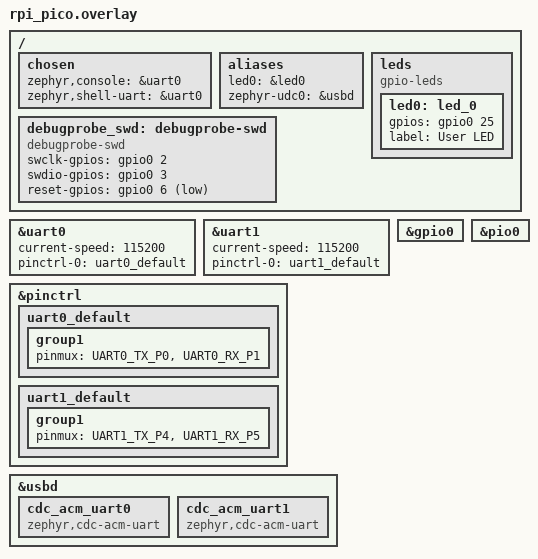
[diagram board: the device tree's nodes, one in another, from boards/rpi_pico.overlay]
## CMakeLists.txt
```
# SPDX-License-Identifier: MIT
# Copyright (c) 2026 Vincent Jardin <vjardin@free.fr>
#
# Debugprobe Zephyr Port - CMakeLists.txt
#
# This is a port of the Raspberry Pi Debug Probe firmware from FreeRTOS to Zephyr.
# Original: https://github.com/raspberrypi/debugprobe

cmake_minimum_required(VERSION 3.20.0)

# Add custom devicetree bindings (for debugprobe-swd)
list(APPEND DTS_ROOT ${CMAKE_CURRENT_SOURCE_DIR})

find_package(Zephyr REQUIRED HINTS $ENV{ZEPHYR_BASE})

project(debugprobe_zephyr VERSION 1.0.0 LANGUAGES C)

# Source files - always compiled
target_sources(app PRIVATE
    src/main.c
    src/get_serial.c
    src/led.c
)

# USB device support
if(CONFIG_USB_DEVICE_STACK_NEXT)
    target_sources(app PRIVATE
        src/debugprobe_usbd.c
    )
    # USBD DAP requires both USB and DAP to be enabled
    if(CONFIG_DEBUGPROBE_DAP)
        target_sources(app PRIVATE
            src/usbd_dap.c
        )
    endif()
endif()

# DAP support
if(CONFIG_DEBUGPROBE_DAP)
    target_sources(app PRIVATE
        src/probe.c
        src/dap.c
        src/dap_vendor.c
        src/swo.c
        src/swdio.c
        src/watchdog.c
    )
endif()

# CDC UART support
if(CONFIG_DEBUGPROBE_CDC_UART)
    target_sources(app PRIVATE
        src/cdc_uart.c
    )
endif()

# PIO-based features for RP2040
if(CONFIG_SOC_RP2040)
    target_sources(app PRIVATE
        src/pio_swd.c
        src/autobaud.c
    )

    # PIO assembly compilation
    include(${CMAKE_CURRENT_SOURCE_DIR}/cmake/pioasm.cmake)

    # Generate PIO headers from .pio source files
    set(PIO_GENERATED_DIR ${CMAKE_CURRENT_BINARY_DIR}/generated/pio)
    file(MAKE_DIRECTORY ${PIO_GENERATED_DIR})

    pioasm_generate_header(
        PIO_FILE ${CMAKE_CURRENT_SOURCE_DIR}/src/pio/probe.pio
        OUTPUT_DIR ${PIO_GENERATED_DIR}
    )

    pioasm_generate_header(
        PIO_FILE ${CMAKE_CURRENT_SOURCE_DIR}/src/pio/probe_oen.pio
        OUTPUT_DIR ${PIO_GENERATED_DIR}
    )

    # Add generated headers as dependencies if pioasm is available
    if(PIOASM_GENERATED)
        add_dependencies(app probe_pio_header probe_oen_pio_header)
        target_compile_definitions(app PRIVATE
            PIO_GENERATED_HEADERS=1
        )
    endif()

    # Add generated header directory to include path
    target_include_directories(app PRIVATE
        ${PIO_GENERATED_DIR}
    )
endif()

# Include directories
target_include_directories(app PRIVATE
    include
    ${ZEPHYR_BASE}/include
)

# Compile definitions
target_compile_definitions(app PRIVATE
    DEBUGPROBE_VERSION="${PROJECT_VERSION}"
)

# Enable LTO for size optimization (optional)
if(CONFIG_LTO)
    set_property(TARGET app PROPERTY INTERPROCEDURAL_OPTIMIZATION TRUE)
endif()
```

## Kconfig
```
# SPDX-License-Identifier: MIT
# Copyright (c) 2026 Vincent Jardin <vjardin@free.fr>
#
# Debugprobe Zephyr Port - Kconfig

mainmenu "Debugprobe Zephyr Configuration"

config DEBUGPROBE
	bool "Enable Debug Probe functionality"
	default y
	help
	  Enable the debug probe CMSIS-DAP and UART bridge functionality.

config DEBUGPROBE_CDC_UART
	bool "Enable CDC UART bridge"
	default y
	depends on DEBUGPROBE
	help
	  Enable USB CDC to UART bridge functionality.

config DEBUGPROBE_DAP
	bool "Enable CMSIS-DAP interface"
	default y
	depends on DEBUGPROBE
	help
	  Enable CMSIS-DAP debug interface for SWD debugging.

config DEBUGPROBE_PIO_SWD
	bool "Use PIO for high-speed SWD"
	default y
	depends on DEBUGPROBE_DAP && SOC_RP2040
	help
	  Use RP2040's Programmable I/O (PIO) for high-speed SWD operations.
	  This provides significantly better performance than GPIO bit-banging.
	  When disabled, GPIO bit-banging is used instead.

config DEBUGPROBE_UART_BAUDRATE
	int "Default UART baudrate"
	default 115200
	depends on DEBUGPROBE_CDC_UART
	help
	  Default baudrate for the UART bridge.

config DEBUGPROBE_DAP_CLOCK_HZ
	int "DAP SWD clock frequency (Hz)"
	default 1000000
	depends on DEBUGPROBE_DAP
	help
	  SWD clock frequency in Hz. Default is 1MHz.

config DEBUGPROBE_TX_LED
	bool "Enable TX LED indicator"
	default y
	help
	  Enable LED indicator for UART TX activity.

config DEBUGPROBE_RX_LED
	bool "Enable RX LED indicator"
	default y
	help
	  Enable LED indicator for UART RX activity.

config DEBUGPROBE_DAP_LED
	bool "Enable DAP activity LED"
	default y
	help
	  Enable LED indicator for DAP/SWD activity.

config DEBUGPROBE_AUTOBAUD
	bool "Enable auto-baud detection"
	default y
	depends on DEBUGPROBE_CDC_UART
	help
	  Enable automatic baud rate detection for UART.

config DEBUGPROBE_USB_VID
	hex "USB Vendor ID"
	default 0x2E8A
	help
	  USB Vendor ID for the debug probe.

config DEBUGPROBE_USB_PID
	hex "USB Product ID"
	default 0x000C
	help
	  USB Product ID for the debug probe.

# Thread priorities (higher value = higher priority in Zephyr)
config DEBUGPROBE_UART_THREAD_PRIORITY
	int "UART thread priority"
	default 5
	help
	  Priority for the UART bridge thread.

config DEBUGPROBE_DAP_THREAD_PRIORITY
	int "DAP thread priority"
	default 4
	help
	  Priority for the DAP handler thread.

config DEBUGPROBE_USB_THREAD_PRIORITY
	int "USB thread priority"
	default 6
	help
	  Priority for the USB handler thread.

# Stack sizes
config DEBUGPROBE_UART_STACK_SIZE
	int "UART thread stack size"
	default 1024
	help
	  Stack size for UART thread.

config DEBUGPROBE_DAP_STACK_SIZE
	int "DAP thread stack size"
	default 1024
	help
	  Stack size for DAP thread.

config DEBUGPROBE_USB_STACK_SIZE
	int "USB thread stack size"
	default 1024
	help
	  Stack size for USB thread.

source "Kconfig.zephyr"
```

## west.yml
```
manifest:
  remotes:
    - name: zephyrproject-rtos
      url-base: https://github.com/zephyrproject-rtos

  projects:
    - name: zephyr
      remote: zephyrproject-rtos
      revision: main
      import:
        name-allowlist:
          - cmsis
          - cmsis_6
          - hal_rpi_pico

  self:
    path: debugprobe
```

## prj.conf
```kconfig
# SPDX-License-Identifier: MIT
# Copyright (c) 2026 Vincent Jardin <vjardin@free.fr>
#
# Debugprobe Zephyr Port - Project Configuration

# General
CONFIG_MAIN_STACK_SIZE=2048
CONFIG_SYSTEM_WORKQUEUE_STACK_SIZE=2048
CONFIG_HEAP_MEM_POOL_SIZE=8192

# Enable GPIO
CONFIG_GPIO=y

# Enable UART
CONFIG_SERIAL=y
CONFIG_UART_INTERRUPT_DRIVEN=y
CONFIG_UART_LINE_CTRL=y

# Console over USB CDC ACM
CONFIG_CONSOLE=y
CONFIG_UART_CONSOLE=y
CONFIG_PRINTK=y

# Shell for debugging
CONFIG_SHELL=y
CONFIG_SHELL_BACKEND_SERIAL=y
CONFIG_SHELL_PROMPT_UART="debugprobe:~$ "
CONFIG_SHELL_CMDS=y
CONFIG_SHELL_TAB=y
CONFIG_SHELL_TAB_AUTOCOMPLETION=y
CONFIG_SHELL_HISTORY=y
CONFIG_SHELL_HELP=y
CONFIG_SHELL_VT100_COLORS=y
CONFIG_SHELL_METAKEYS=y

# Built-in shell commands for debugging
CONFIG_KERNEL_SHELL=y
CONFIG_DEVICE_SHELL=y
CONFIG_GPIO_SHELL=y
CONFIG_LOG_CMDS=y
CONFIG_REBOOT=y

# Enable new USB device stack
CONFIG_USB_DEVICE_STACK_NEXT=y
CONFIG_USBD_CDC_ACM_CLASS=y
# Disable auto-init - debugprobe_usbd.c handles USB registration
CONFIG_CDC_ACM_SERIAL_INITIALIZE_AT_BOOT=n

# USB device descriptors (configured via USBD_DEVICE_DEFINE)
# VID/PID set in code: 0x2E8A/0x000C

# Logging for USB (suppress CDC ACM logs to prevent recursion when used as console)
CONFIG_USBD_LOG_LEVEL_WRN=y
CONFIG_UDC_DRIVER_LOG_LEVEL_WRN=y
CONFIG_USBD_CDC_ACM_LOG_LEVEL_OFF=y

# Thread support
CONFIG_MULTITHREADING=y
CONFIG_NUM_PREEMPT_PRIORITIES=16

# Timing
CONFIG_SYS_CLOCK_TICKS_PER_SEC=1000

# Debug/logging
CONFIG_LOG=y
CONFIG_LOG_DEFAULT_LEVEL=2
CONFIG_SHELL_LOG_BACKEND=y

# Ring buffer for USB data
CONFIG_RING_BUFFER=y

# Net buffer for USB device stack
CONFIG_NET_BUF=y

# Flash for storing serial number
CONFIG_FLASH=y
CONFIG_FLASH_PAGE_LAYOUT=y

# Enable PIO (RP2040 specific)
CONFIG_PIO_RPI_PICO=y

# Debugprobe specific
CONFIG_DEBUGPROBE=y
CONFIG_DEBUGPROBE_CDC_UART=y
CONFIG_DEBUGPROBE_DAP=y
CONFIG_DEBUGPROBE_TX_LED=y
CONFIG_DEBUGPROBE_RX_LED=y
CONFIG_DEBUGPROBE_DAP_LED=y

# Optimize for size
CONFIG_SIZE_OPTIMIZATIONS=y
```

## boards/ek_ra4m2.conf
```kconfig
# SPDX-License-Identifier: MIT
# Copyright (c) 2026 Vincent Jardin <vjardin@free.fr>
#
# Debugprobe Zephyr Port - Board configuration for Renesas EK-RA4M2
#
# Hardware Setup:
#   - USB CDC ACM: Console (on-board USB)
#   - SCI9 (UART9): Target UART bridge via Arduino SPI header (J24)
#   - GPIO: SWD bit-bang via Arduino digital header (J23)
#
# See boards/ek_ra4m2.overlay for detailed wiring instructions.

# Disable RP2040-specific PIO features
CONFIG_PIO_RPI_PICO=n

# Enable DAP with GPIO bit-bang SWD (via devicetree debugprobe-swd node)
CONFIG_DEBUGPROBE_DAP=y

# Enable CDC UART bridge (uses SCI9/uart9 on Arduino SPI header)
# NOTE: Requires cdc_uart.c modification to use uart9 instead of uart1
CONFIG_DEBUGPROBE_CDC_UART=n

# Disable LED activity indicators (no dedicated LEDs configured)
CONFIG_DEBUGPROBE_TX_LED=n
CONFIG_DEBUGPROBE_RX_LED=n
CONFIG_DEBUGPROBE_DAP_LED=n

# Disable autobaud (RP2040-specific PIO feature)
CONFIG_DEBUGPROBE_AUTOBAUD=n

# Flash support for serial number storage
CONFIG_FLASH=y
CONFIG_FLASH_PAGE_LAYOUT=y

# Enable GPIO for SWD bit-bang pins
CONFIG_GPIO=y
```

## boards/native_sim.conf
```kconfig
# SPDX-License-Identifier: MIT
#
# Debugprobe Zephyr Port - native_sim configuration
#
# This configuration is for compile-time verification only.
# The debugprobe cannot fully run on native_sim due to hardware dependencies.

# Disable hardware-specific features
CONFIG_FLASH=n
CONFIG_FLASH_PAGE_LAYOUT=n

# Disable USB device stack (not supported on native_sim)
CONFIG_USB_DEVICE_STACK_NEXT=n
CONFIG_USBD_CDC_ACM_CLASS=n

# Disable debugprobe features that require hardware
CONFIG_DEBUGPROBE=y
CONFIG_DEBUGPROBE_CDC_UART=n
CONFIG_DEBUGPROBE_DAP=n
CONFIG_DEBUGPROBE_TX_LED=n
CONFIG_DEBUGPROBE_RX_LED=n
CONFIG_DEBUGPROBE_DAP_LED=n
CONFIG_DEBUGPROBE_AUTOBAUD=n

# Keep basic infrastructure for compile checking
CONFIG_GPIO=y
CONFIG_SERIAL=y
CONFIG_LOG=y
CONFIG_LOG_DEFAULT_LEVEL=2
```

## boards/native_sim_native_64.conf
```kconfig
# SPDX-License-Identifier: MIT
# Copyright (c) 2026 Vincent Jardin <vjardin@free.fr>
#
# Debugprobe Zephyr Port - native_sim configuration
#
# This configuration enables virtual USB for testing the USB stack
# without real hardware using USB/IP and UVB (USB Virtual Bus).

# Disable hardware-specific features not available on native_sim
CONFIG_FLASH=n
CONFIG_FLASH_PAGE_LAYOUT=n

# Disable RP2040-specific PIO driver
CONFIG_PIO_RPI_PICO=n

# Enable USB device stack with virtual USB controller
CONFIG_USB_DEVICE_STACK_NEXT=y
CONFIG_USBD_CDC_ACM_CLASS=y
CONFIG_UDC_DRIVER_LOG_LEVEL_WRN=y
CONFIG_USBD_LOG_LEVEL_WRN=y

# Virtual USB Bus (UVB) for connecting virtual UDC and UHC
CONFIG_UVB=y
CONFIG_UVB_LOG_LEVEL_WRN=y

# USB Host stack (required for USB/IP integration)
CONFIG_USB_HOST_STACK=y
CONFIG_USBH_LOG_LEVEL_WRN=y
CONFIG_UHC_DRIVER_LOG_LEVEL_WRN=y

# USB/IP support for host-side testing
CONFIG_USBIP=y
CONFIG_USBIP_LOG_LEVEL_WRN=y

# Network stack for USB/IP
CONFIG_NETWORKING=y
CONFIG_NET_IPV4=y
CONFIG_NET_TCP=y
CONFIG_NET_SOCKETS=y
CONFIG_NET_CONFIG_SETTINGS=y
CONFIG_NET_CONFIG_NEED_IPV4=y
CONFIG_NET_CONFIG_MY_IPV4_ADDR="192.0.2.1"
CONFIG_NET_CONFIG_PEER_IPV4_ADDR="192.0.2.2"

# USB buffer settings
CONFIG_UHC_BUF_COUNT=32
CONFIG_UHC_XFER_COUNT=32

# Timing - high resolution for USB
CONFIG_SYS_CLOCK_TICKS_PER_SEC=1000000

# Disable debugprobe features that require hardware (SWD, PIO, etc.)
CONFIG_DEBUGPROBE=y
CONFIG_DEBUGPROBE_CDC_UART=y
CONFIG_DEBUGPROBE_DAP=n
CONFIG_DEBUGPROBE_TX_LED=n
CONFIG_DEBUGPROBE_RX_LED=n
CONFIG_DEBUGPROBE_DAP_LED=n
CONFIG_DEBUGPROBE_AUTOBAUD=n

# Keep basic infrastructure
CONFIG_GPIO=y
CONFIG_SERIAL=y
CONFIG_LOG=y
CONFIG_LOG_DEFAULT_LEVEL=3
```

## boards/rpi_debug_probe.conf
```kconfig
# SPDX-License-Identifier: MIT
# Copyright (c) 2026 Vincent Jardin <vjardin@free.fr>
#
# Debugprobe Zephyr Port - Board configuration for Official Raspberry Pi Debug Probe
#

# Flash operations for serial number
CONFIG_FLASH=y
CONFIG_FLASH_PAGE_LAYOUT=y

# PIO support
CONFIG_PIO_RPI_PICO=y
```

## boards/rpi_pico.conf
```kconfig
# SPDX-License-Identifier: MIT
# Copyright (c) 2026 Vincent Jardin <vjardin@free.fr>
#
# Debugprobe Zephyr Port - Board configuration for Raspberry Pi Pico
#

# Flash operations for serial number
CONFIG_FLASH=y
CONFIG_FLASH_PAGE_LAYOUT=y

# PIO support
CONFIG_PIO_RPI_PICO=y
```

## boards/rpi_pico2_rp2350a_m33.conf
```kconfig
# SPDX-License-Identifier: MIT
# Copyright (c) 2026 Vincent Jardin <vjardin@free.fr>
#
# Debugprobe Zephyr Port - Board configuration for Raspberry Pi Pico 2 (RP2350)
#

# Flash operations for serial number
CONFIG_FLASH=y
CONFIG_FLASH_PAGE_LAYOUT=y

# PIO support (RP2350 has 3 PIO blocks)
CONFIG_PIO_RPI_PICO=y
```

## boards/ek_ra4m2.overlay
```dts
/*
 * SPDX-License-Identifier: MIT
 * Copyright (c) 2026 Vincent Jardin <vjardin@free.fr>
 *
 * Debugprobe Zephyr Port - Device Tree Overlay for Renesas EK-RA4M2
 *
 * ============================================================================
 * HARDWARE SETUP GUIDE
 * ============================================================================
 *
 * This overlay configures the EK-RA4M2 evaluation board as a debug probe with:
 *   - USB CDC ACM for host communication (on-board USB connector)
 *   - SCI9 UART for target UART bridge (directly from Arduino SPI header)
 *   - GPIO bit-bang for SWD debugging (directly from Arduino digital header)
 *
 * ============================================================================
 * PIN ACTIVE (No Additional Hardware Needed)
 * ============================================================================
 *
 *   +-- Arduino Headers on EK-RA4M2 Board --+
 *   |                                        |
 *   |  Header J24 (directly usable):         |
 *   |  +----------------------------------+  |
 *   |  | Pin | Signal   | MCU   | Function | |
 *   |  |-----|----------|-------|----------| |
 *   |  | 4   | D11/MOSI | P602  | TXD9     | |  --> Target RXD
 *   |  | 5   | D12/MISO | P601  | RXD9     | |  <-- Target TXD
 *   |  | 7   | GND      | GND   | Ground   | |  --- Target GND
 *   |  +----------------------------------+  |
 *   |                                        |
 *   |  Header J23 (directly usable):         |
 *   |  +----------------------------------+  |
 *   |  | Pin | Signal   | MCU   | Function | |
 *   |  |-----|----------|-------|----------| |
 *   |  | 3   | D2       | P304  | SWCLK    | |  --> Target SWCLK
 *   |  | 5   | D4       | P106  | SWDIO    | |  <-> Target SWDIO
 *   |  | 8   | D7       | P107  | nRESET   | |  --> Target nRESET
 *   |  +----------------------------------+  |
 *   |                                        |
 *   +----------------------------------------+
 *
 * ============================================================================
 * CONNECTION DIAGRAMS
 * ============================================================================
 *
 * UART Bridge Connection:
 *   +---------+                           +--------------+
 *   | EK-RA4M2|                           | Target Board |
 *   | J24-4   |--- (TXD9) ------------->  | UART RXD     |
 *   | J24-5   |<-- (RXD9) --------------  | UART TXD     |
 *   | J24-7   |--- (GND) ---------------  | GND          |
 *   +---------+                           +--------------+
 *
 *   SWD Debug Connection:
 *   +---------+                           +----------------+
 *   | EK-RA4M2|                           | Target Board   |
 *   | J23-3   |--- (SWCLK) ------------>  | SWCLK          |
 *   | J23-5   |<-> (SWDIO) ------------>  | SWDIO          |
 *   | J23-8   |--- (nRESET) ----------->  | nRESET (opt)   |
 *   | GND     |--- (GND) -------------->  | GND            |
 *   +---------+                           +----------------+
 *
 * ============================================================================
 * 10-PIN CORTEX DEBUG CONNECTOR ADAPTER
 * ============================================================================
 *
 * If your target uses a standard 10-pin Cortex Debug connector (1.27mm pitch),
 * you can build a simple adapter cable:
 *
 *   Standard 10-pin Cortex Debug Connector Pinout:
 *   +-------+-------+
 *   |  VCC  | SWDIO |  Pin 1 = VCC (do NOT connect to EK-RA4M2)
 *   |  GND  | SWCLK |  Pin 2 = SWDIO <-> J23-5 (P106)
 *   |  GND  |  SWO  |  Pin 3 = GND   --- J23 GND or J24-7
 *   |  KEY  | NC/TDI|  Pin 4 = SWCLK --> J23-3 (P304)
 *   | nRESET|  GND  |  Pin 5 = GND
 *   +-------+-------+  Pin 6 = SWO (not supported)
 *                      Pin 10 = nRESET --> J23-8 (P107)
 *
 * ============================================================================
 * WHAT TO BUY
 * ============================================================================
 *
 * Minimum required:
 *
 *   1. Female-to-Female Dupont Jumper Wires (2.54mm pitch)
 *      - Quantity: 6-8 wires (10cm or 20cm length)
 *      - Example: search "dupont jumper wires female" on Amazon/AliExpress
 *      - Use: Direct connection from Arduino headers to target
 *
 * Optional for Cortex Debug targets:
 *
 *   2. 10-pin 1.27mm IDC connector + ribbon cable
 *      - For targets with standard ARM Cortex Debug connector
 *      - Plus 2.54mm female headers to connect to EK-RA4M2
 *
 *   3. Tag-Connect TC2050-IDC or TC2030-IDC
 *      - Pogo-pin adapter for targets with Tag-Connect footprint
 *
 * ============================================================================
 * WIRING SUMMARY
 * ============================================================================
 *
 * UART Bridge:
 *   EK-RA4M2 Pin     Wire Color (suggest)    Target Pin
 *   ------------     ------------------      ----------
 *   J24-4 (TXD9)     Yellow or Orange   -->  RXD
 *   J24-5 (RXD9)     Green              <--  TXD
 *   J24-7 (GND)      Black              ---  GND
 *
 * SWD Debug:
 *   EK-RA4M2 Pin     Wire Color (suggest)    Target Pin
 *   ------------     ------------------      ----------
 *   J23-3 (SWCLK)    Blue               -->  SWCLK
 *   J23-5 (SWDIO)    White or Purple    <->  SWDIO
 *   J23-8 (nRESET)   Gray               -->  nRESET
 *   Any GND          Black              ---  GND
 *
 * ============================================================================
 * IMPORTANT NOTES
 * ============================================================================
 *
 * - This probe operates at 3.3V logic levels
 * - Do NOT connect directly to 5V targets without level shifters!
 * - Ensure target SWD pins are not active by on-board debugger
 * - Some targets may require removing jumpers to isolate SWD from on-board debug
 *
 * ============================================================================
 */

#include <zephyr/dt-bindings/gpio/gpio.h>

/ {
	chosen {
		/* Use USB CDC ACM for console instead of hardware UART */
		zephyr,console = &cdc_acm_uart0;
		zephyr,shell-uart = &cdc_acm_uart0;
	};

	aliases {
		/* Activity LED - directly on-board user LED */
		led0 = &led1;

		/* UART for CDC bridge to target */
		debugprobe-uart = &uart9;
	};

	/*
	 * SWD GPIO pin definitions for bit-bang implementation
	 * accent the existing Arduino digital header connection
	 */
	debugprobe_swd: debugprobe-swd {
		compatible = "debugprobe-swd";

		/* D2 = P304 (J23 pin 3) - SWCLK output */
		swclk-gpios = <&ioport3 4 GPIO_ACTIVE_HIGH>;

		/* D4 = P106 (J23 pin 5) - SWDIO bidirectional */
		swdio-gpios = <&ioport1 6 GPIO_ACTIVE_HIGH>;

		/* D7 = P107 (J23 pin 8) - nRESET output (directly active-low) */
		reset-gpios = <&ioport1 7 GPIO_ACTIVE_LOW>;
	};
};

/* Enable GPIO ports for SWD pins */
&ioport1 {
	status = "okay";
};

&ioport3 {
	status = "okay";
};

/* Pin control for SCI9 UART on Arduino SPI header */
&pinctrl {
	sci9_default: sci9_default {
		group1 {
			/* TXD9 = P602 (J24 pin 4 / D11), RXD9 = P601 (J24 pin 5 / D12) */
			psels = <RA_PSEL(RA_PSEL_SCI_9, 6, 2)>,  /* TXD9 - Port 6, Pin 2 */
			        <RA_PSEL(RA_PSEL_SCI_9, 6, 1)>;  /* RXD9 - Port 6, Pin 1 */
		};
	};
};

/* Enable SCI9 for UART bridge to target */
&sci9 {
	status = "okay";
	pinctrl-0 = <&sci9_default>;
	pinctrl-names = "default";

	uart9: uart {
		current-speed = <115200>;
		status = "okay";
	};
};

/* USB Device with CDC ACM for console and DAP */
&zephyr_udc0 {
	cdc_acm_uart0: cdc_acm_uart0 {
		compatible = "zephyr,cdc-acm-uart";
	};
};
```

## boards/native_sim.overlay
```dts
/*
 * SPDX-License-Identifier: MIT
 * Copyright (c) 2026 Vincent Jardin <vjardin@free.fr>
 *
 * Debugprobe Zephyr Port - Device Tree Overlay for native_sim (32-bit)
 *
 * This overlay enables virtual USB device support for testing
 * the USB stack without real hardware using USB/IP and UVB (USB Virtual Bus).
 */

/* Remove the default native-posix-udc which doesn't support USB_DEVICE_STACK_NEXT */
/delete-node/ &zephyr_udc0;

/ {
	chosen {
		zephyr,console = &uart0;
		zephyr,shell-uart = &uart0;
	};

	/* Virtual USB Host Controller with nested Virtual USB Device Controller */
	zephyr_uhc0: uhc_vrt0 {
		compatible = "zephyr,uhc-virtual";

		zephyr_udc0: udc_vrt0 {
			compatible = "zephyr,udc-virtual";
			num-bidir-endpoints = <8>;
			maximum-speed = "high-speed";
		};
	};

	aliases {
		zephyr-udc0 = &zephyr_udc0;
	};
};

/* Enable uart1 for CDC UART bridge functionality */
&uart1 {
	status = "okay";
};

/* Add CDC ACM UART to the virtual USB device controller */
&zephyr_udc0 {
	/* CDC ACM #0 - Console */
	cdc_acm_uart0: cdc_acm_uart0 {
		compatible = "zephyr,cdc-acm-uart";
	};

	/* CDC ACM #1 - UART bridge to target */
	cdc_acm_uart1: cdc_acm_uart1 {
		compatible = "zephyr,cdc-acm-uart";
	};
};
```

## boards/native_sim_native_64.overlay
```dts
/*
 * SPDX-License-Identifier: MIT
 * Copyright (c) 2026 Vincent Jardin <vjardin@free.fr>
 *
 * Debugprobe Zephyr Port - Device Tree Overlay for native_sim (64-bit)
 *
 * This overlay enables virtual USB device support for testing
 * the USB stack without real hardware using USB/IP and UVB (USB Virtual Bus).
 */

/* Remove the default native-posix-udc which doesn't support USB_DEVICE_STACK_NEXT */
/delete-node/ &zephyr_udc0;

/ {
	chosen {
		zephyr,console = &uart0;
		zephyr,shell-uart = &uart0;
	};

	/* Virtual USB Host Controller with nested Virtual USB Device Controller */
	zephyr_uhc0: uhc_vrt0 {
		compatible = "zephyr,uhc-virtual";

		zephyr_udc0: udc_vrt0 {
			compatible = "zephyr,udc-virtual";
			num-bidir-endpoints = <8>;
			maximum-speed = "high-speed";
		};
	};

	aliases {
		zephyr-udc0 = &zephyr_udc0;
	};
};

/* Enable uart1 for CDC UART bridge functionality */
&uart1 {
	status = "okay";
};

/* Add CDC ACM UART to the virtual USB device controller */
&zephyr_udc0 {
	/* CDC ACM #0 - Console */
	cdc_acm_uart0: cdc_acm_uart0 {
		compatible = "zephyr,cdc-acm-uart";
	};

	/* CDC ACM #1 - UART bridge to target */
	cdc_acm_uart1: cdc_acm_uart1 {
		compatible = "zephyr,cdc-acm-uart";
	};
};
```

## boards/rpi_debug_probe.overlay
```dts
/*
 * SPDX-License-Identifier: MIT
 * Copyright (c) 2026 Vincent Jardin <vjardin@free.fr>
 *
 * Debugprobe Zephyr Port - Device Tree Overlay for Official Raspberry Pi Debug Probe
 *
 * Official Debug Probe hardware with level shifters and dedicated SWD connector.
 * Pin assignments match the original debugprobe firmware.
 *
 * LEDs (accent from base DTS):
 *   - GPIO2:  Red LED (D1) - USB connected indicator
 *   - GPIO7:  Green LED UART (D2) - UART RX activity
 *   - GPIO8:  Yellow LED UART (D3) - UART TX activity
 *   - GPIO15: Green LED DBUG (D4) - DAP connected
 *   - GPIO16: Yellow LED DBUG (D5) - DAP running
 *
 * SWD Interface:
 *   - GPIO11: SWCLK
 *   - GPIO12: SWDIO
 *   - GPIO14: nRESET (directly active-low)
 *   - GPIO10: OEN (level shifter output enable)
 *   - GPIO13: DIR (level shifter direction)
 *
 * Target UART (directly active UART1 from base DTS on GP4/GP5)
 */

#include <zephyr/dt-bindings/gpio/gpio.h>

/ {
    chosen {
        /* Console over USB CDC ACM */
        zephyr,console = &cdc_acm_uart0;
        zephyr,shell-uart = &cdc_acm_uart0;
    };

    aliases {
        led0 = &red_led;
        zephyr-udc0 = &usbd;
        /* LED aliases for firmware */
        led-usb-connected = &red_led;
        led-uart-rx = &green_led_uart;
        led-uart-tx = &yellow_led_uart;
        led-dap-connected = &green_led_dbug;
        led-dap-running = &yellow_led_dbug;
    };

    /*
     * SWD GPIO pin definitions for official Debug Probe hardware
     * Uses level shifters with direction control
     */
    debugprobe_swd: debugprobe-swd {
        compatible = "debugprobe-swd";

        /* GP11 - SWCLK output */
        swclk-gpios = <&gpio0 11 GPIO_ACTIVE_HIGH>;

        /* GP12 - SWDIO bidirectional */
        swdio-gpios = <&gpio0 12 GPIO_ACTIVE_HIGH>;

        /* GP14 - nRESET output (directly active-low) */
        reset-gpios = <&gpio0 14 GPIO_ACTIVE_LOW>;
    };
};

/* USB Device with two CDC ACM interfaces */
&usbd {
    status = "okay";

    /* CDC ACM #0 - Console/Debug output */
    cdc_acm_uart0: cdc_acm_uart0 {
        compatible = "zephyr,cdc-acm-uart";
    };

    /* CDC ACM #1 - UART bridge to target (J2 connector) */
    cdc_acm_uart1: cdc_acm_uart1 {
        compatible = "zephyr,cdc-acm-uart";
    };
};

/* PIO for high-speed SWD */
&pio0 {
    status = "okay";
};
```

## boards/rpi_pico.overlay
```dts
/*
 * SPDX-License-Identifier: MIT
 * Copyright (c) 2026 Vincent Jardin <vjardin@free.fr>
 *
 * Debugprobe Zephyr Port - Device Tree Overlay for Raspberry Pi Pico
 */

#include <zephyr/dt-bindings/gpio/gpio.h>

/ {
    chosen {
        zephyr,console = &uart0;
        zephyr,shell-uart = &uart0;
    };

    aliases {
        led0 = &led0;
        zephyr-udc0 = &usbd;
    };

    leds {
        compatible = "gpio-leds";
        led0: led_0 {
            gpios = <&gpio0 25 GPIO_ACTIVE_HIGH>;
            label = "User LED";
        };
    };

    /*
     * SWD GPIO pin definitions
     * Used as fallback when PIO is not available or for compatibility
     * PIO acceleration is used when available (see pio_swd.c)
     */
    debugprobe_swd: debugprobe-swd {
        compatible = "debugprobe-swd";

        /* GP2 - SWCLK output */
        swclk-gpios = <&gpio0 2 GPIO_ACTIVE_HIGH>;

        /* GP3 - SWDIO bidirectional */
        swdio-gpios = <&gpio0 3 GPIO_ACTIVE_HIGH>;

        /* GP6 - nRESET output (directly active-low) */
        reset-gpios = <&gpio0 6 GPIO_ACTIVE_LOW>;
    };
};

/* Debug UART for console */
&uart0 {
    status = "okay";
    current-speed = <115200>;
    pinctrl-0 = <&uart0_default>;
    pinctrl-names = "default";
};

/* Bridge UART */
&uart1 {
    status = "okay";
    current-speed = <115200>;
    pinctrl-0 = <&uart1_default>;
    pinctrl-names = "default";
};

/* Pin control */
&pinctrl {
    uart0_default: uart0_default {
        group1 {
            pinmux = <UART0_TX_P0>, <UART0_RX_P1>;
        };
    };

    uart1_default: uart1_default {
        group1 {
            pinmux = <UART1_TX_P4>, <UART1_RX_P5>;
        };
    };
};

/* GPIO for SWD pins and LEDs */
&gpio0 {
    status = "okay";
};

/* USB Device with CDC ACM */
&usbd {
    status = "okay";

    /* CDC ACM #0 - available for host communication */
    cdc_acm_uart0: cdc_acm_uart0 {
        compatible = "zephyr,cdc-acm-uart";
    };

    /* CDC ACM #1 - UART bridge to target */
    cdc_acm_uart1: cdc_acm_uart1 {
        compatible = "zephyr,cdc-acm-uart";
    };
};

/* PIO for high-speed SWD */
&pio0 {
    status = "okay";
};
```

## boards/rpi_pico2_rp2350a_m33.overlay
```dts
/*
 * SPDX-License-Identifier: MIT
 * Copyright (c) 2026 Vincent Jardin <vjardin@free.fr>
 *
 * Debugprobe Zephyr Port - Device Tree Overlay for Raspberry Pi Pico 2 (RP2350)
 *
 * Pin-compatible with Pico, uses same GPIO assignments.
 * RP2350 features enhanced PIO (3 blocks) and Cortex-M33 cores.
 */

#include <zephyr/dt-bindings/gpio/gpio.h>
#include <zephyr/dt-bindings/pinctrl/rpi-pico-rp2350a-pinctrl.h>

/ {
    chosen {
        zephyr,console = &uart0;
        zephyr,shell-uart = &uart0;
    };

    aliases {
        led0 = &led0;
        zephyr-udc0 = &usbd;
    };

    /*
     * SWD GPIO pin definitions
     * Used as fallback when PIO is not available or for compatibility
     * PIO acceleration is used when available (see pio_swd.c)
     */
    debugprobe_swd: debugprobe-swd {
        compatible = "debugprobe-swd";

        /* GP2 - SWCLK output */
        swclk-gpios = <&gpio0 2 GPIO_ACTIVE_HIGH>;

        /* GP3 - SWDIO bidirectional */
        swdio-gpios = <&gpio0 3 GPIO_ACTIVE_HIGH>;

        /* GP6 - nRESET output (directly active-low) */
        reset-gpios = <&gpio0 6 GPIO_ACTIVE_LOW>;
    };
};

/* Debug UART for console */
&uart0 {
    status = "okay";
    current-speed = <115200>;
    pinctrl-0 = <&uart0_default>;
    pinctrl-names = "default";
};

/* Bridge UART */
&uart1 {
    status = "okay";
    current-speed = <115200>;
    pinctrl-0 = <&uart1_default>;
    pinctrl-names = "default";
};

/* Pin control */
&pinctrl {
    uart0_default: uart0_default {
        group1 {
            pinmux = <UART0_TX_P0>, <UART0_RX_P1>;
        };
    };

    uart1_default: uart1_default {
        group1 {
            pinmux = <UART1_TX_P4>, <UART1_RX_P5>;
        };
    };
};

/* GPIO for SWD pins and LEDs */
&gpio0 {
    status = "okay";
};

/* USB Device with CDC ACM */
&usbd {
    status = "okay";

    /* CDC ACM #0 - available for host communication */
    cdc_acm_uart0: cdc_acm_uart0 {
        compatible = "zephyr,cdc-acm-uart";
    };

    /* CDC ACM #1 - UART bridge to target */
    cdc_acm_uart1: cdc_acm_uart1 {
        compatible = "zephyr,cdc-acm-uart";
    };
};

/* PIO for high-speed SWD - RP2350 has 3 PIO blocks */
&pio0 {
    status = "okay";
};
```

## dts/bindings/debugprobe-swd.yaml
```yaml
# SPDX-License-Identifier: MIT
# Copyright (c) 2026 Vincent Jardin <vjardin@free.fr>
#
# Debugprobe SWD Interface Devicetree Binding
#
# This binding defines the GPIO pins used for SWD (Serial Wire Debug)
# bit-bang implementation. Supports multiple GPIO controllers.

description: |
  Debug probe SWD interface GPIO configuration.

  This node defines the GPIO pins for SWD debugging:
  - swclk: Serial Wire Clock (output)
  - swdio: Serial Wire Data I/O (bidirectional)
  - reset: Target reset (optional, active low)
  - swdir: Direction control for level shifter (optional)

  Example:
    debugprobe_swd: debugprobe-swd {
        compatible = "debugprobe-swd";
        swclk-gpios = <&gpio0 2 GPIO_ACTIVE_HIGH>;
        swdio-gpios = <&gpio0 3 GPIO_ACTIVE_HIGH>;
        reset-gpios = <&gpio0 6 GPIO_ACTIVE_LOW>;
    };

compatible: "debugprobe-swd"

properties:
  swclk-gpios:
    type: phandle-array
    required: true
    description: |
      GPIO pin for SWD clock (SWCLK).
      This is an output pin that generates the debug clock.

  swdio-gpios:
    type: phandle-array
    required: true
    description: |
      GPIO pin for SWD data I/O (SWDIO).
      This is a bidirectional pin for debug data.

  reset-gpios:
    type: phandle-array
    description: |
      GPIO pin for target reset (nRESET).
      This is typically active-low and open-drain.
      Optional - if not specified, reset functionality is disabled.

  swdir-gpios:
    type: phandle-array
    description: |
      GPIO pin for SWDIO direction control.
      Used with level shifters that need explicit direction control.
      High = output (to target), Low = input (from target).
      Optional - only needed for certain hardware designs.

  io-enable-gpios:
    type: phandle-array
    description: |
      GPIO pin for I/O buffer enable.
      Used to enable/disable level shifters or output buffers.
      Optional - only needed for certain hardware designs.
```

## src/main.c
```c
/* SPDX-License-Identifier: MIT
 * Copyright (c) 2021-2023 Raspberry Pi (Trading) Ltd.
 * Copyright (c) 2026 Vincent Jardin <vjardin@free.fr>
 *
 * Debugprobe Zephyr Port - Main Entry Point
 *
 * Port of Raspberry Pi Debug Probe firmware from FreeRTOS to Zephyr RTOS
 * Original: https://github.com/raspberrypi/debugprobe
 *
 * This file replaces the FreeRTOS-based main.c with Zephyr equivalents:
 * - xTaskCreate() -> K_THREAD_DEFINE() or k_thread_create()
 * - vTaskDelay() -> k_sleep()
 * - vTaskDelayUntil() -> k_sleep() with timing calculation
 * - TaskHandle_t -> k_tid_t
 * - Queues -> k_msgq
 * - Semaphores -> k_sem
 */

#include <zephyr/kernel.h>
#include <zephyr/device.h>
#include <zephyr/drivers/gpio.h>
#include <zephyr/drivers/uart.h>
#include <zephyr/logging/log.h>
#include <zephyr/sys/ring_buffer.h>
#include <string.h>

#ifdef CONFIG_USB_DEVICE_STACK_NEXT
#include <zephyr/usb/usbd.h>
#include "usbd_init.h"
#endif

#include "probe_config.h"
#include "led.h"
#ifdef CONFIG_DEBUGPROBE_DAP
#include "probe.h"
#include "dap.h"
#endif
#ifdef CONFIG_DEBUGPROBE_CDC_UART
#include "cdc_uart.h"
#endif
#include "get_serial.h"

LOG_MODULE_REGISTER(debugprobe, CONFIG_LOG_DEFAULT_LEVEL);

#ifdef CONFIG_USB_DEVICE_STACK_NEXT
/* Thread stacks - only UART thread needed, DAP uses usbd_dap.c's thread */
#ifdef CONFIG_DEBUGPROBE_CDC_UART
K_THREAD_STACK_DEFINE(uart_thread_stack, UART_THREAD_STACK_SIZE);
static struct k_thread uart_thread_data;
static k_tid_t uart_tid;

/* Ring buffers for USB-UART bridge */
RING_BUF_DECLARE(uart_tx_ringbuf, USB_TX_BUF_SIZE);
RING_BUF_DECLARE(uart_rx_ringbuf, USB_RX_BUF_SIZE);
#endif

/* USB enabled flag */
static volatile bool usb_configured = false;
#endif /* CONFIG_USB_DEVICE_STACK_NEXT */

/* GPIO device - defined in probe.c, declared extern in DAP_config.h */

#ifdef CONFIG_USB_DEVICE_STACK_NEXT
#ifdef CONFIG_DEBUGPROBE_CDC_UART
/*
 * UART Thread - Handles CDC-UART bridge
 * Replaces: cdc_thread() with xTaskCreate(cdc_thread, "UART", ...)
 */
static void uart_thread_entry(void *p1, void *p2, void *p3)
{
    ARG_UNUSED(p1);
    ARG_UNUSED(p2);
    ARG_UNUSED(p3);

    LOG_INF("UART thread started");

    cdc_uart_init();

    while (1) {
        /* Handle UART <-> USB CDC bridge */
        cdc_uart_task();

        /* Sleep to yield CPU - use short sleep for responsiveness */
        k_sleep(K_USEC(100));
    }
}
#endif /* CONFIG_DEBUGPROBE_CDC_UART */
#endif /* CONFIG_USB_DEVICE_STACK_NEXT */

#ifdef CONFIG_DEBUGPROBE_DAP
/*
 * GPIO Initialization
 *
 * Note: gpio_dev is initialized by probe_gpio_init() in probe.c.
 * It may be NULL on boards without gpio0 (e.g., RA4M2 uses ioport*).
 */
static int gpio_init_pins(void)
{
    int ret;

    /* Configure SWD pins first - this also initializes gpio_dev */
    ret = probe_gpio_init();
    if (ret < 0) {
        LOG_ERR("Failed to initialize probe GPIO");
        return ret;
    }

    /* LED initialization is now handled by led_init() */

    return 0;
}
#endif /* CONFIG_DEBUGPROBE_DAP */

#ifdef CONFIG_USB_DEVICE_STACK_NEXT
/*
 * Suspend worker threads
 * Called when USB is disconnected/suspended to reduce power consumption
 */
static void suspend_threads(void)
{
#ifdef CONFIG_DEBUGPROBE_CDC_UART
    if (uart_tid) {
        k_thread_suspend(uart_tid);
        LOG_DBG("UART thread suspended");
    }
#endif
    /* Note: DAP thread is managed by usbd_dap.c via semaphores */
}

/*
 * Resume worker threads
 * Called when USB is connected/resumed
 */
static void resume_threads(void)
{
#ifdef CONFIG_DEBUGPROBE_CDC_UART
    if (uart_tid) {
        k_thread_resume(uart_tid);
        LOG_DBG("UART thread resumed");
    }
#endif
    /* Note: DAP thread is managed by usbd_dap.c via semaphores */
}

/* USB device context */
static struct usbd_context *usbd_ctx;

/*
 * USB Message Callback
 * Handles USB connection state changes using new stack message system
 */
static void usb_msg_cb(struct usbd_context *const ctx,
                       const struct usbd_msg *msg)
{
    static bool was_configured = false;

    LOG_DBG("USB message: %s", usbd_msg_type_string(msg->type));

    switch (msg->type) {
    case USBD_MSG_CONFIGURATION:
        LOG_INF("USB configured");
        usb_configured = true;
        led_usb_connected(true);
        if (!was_configured) {
            resume_threads();
        }
        was_configured = true;
        break;

    case USBD_MSG_RESET:
        LOG_INF("USB reset");
        usb_configured = false;
        led_usb_connected(false);
        /* Keep threads running during reset - they'll be needed once reconfigured */
        break;

    case USBD_MSG_SUSPEND:
        LOG_INF("USB suspended");
        led_usb_connected(false);
        if (was_configured) {
            suspend_threads();
        }
        break;

    case USBD_MSG_RESUME:
        LOG_INF("USB resumed");
        led_usb_connected(true);
        if (was_configured) {
            resume_threads();
        }
        break;

    case USBD_MSG_CDC_ACM_LINE_CODING:
        /* Baud rate change - handled by cdc_uart via uart_line_ctrl_get */
        LOG_DBG("CDC ACM line coding changed");
        break;

    case USBD_MSG_CDC_ACM_CONTROL_LINE_STATE:
        /* DTR/RTS change */
        LOG_DBG("CDC ACM control line state changed");
        break;

    default:
        break;
    }
}
#endif /* CONFIG_USB_DEVICE_STACK_NEXT */

/*
 * Main Entry Point
 * Replaces FreeRTOS main() with Zephyr threading
 */
int main(void)
{
    char serial[17];
    int ret;

    /* Initialize LEDs first for visual feedback */
    ret = led_init();
    if (ret < 0) {
        LOG_WRN("LED init failed: %d", ret);
    }

    LOG_INF("Debug Probe (Zephyr) starting...");
    LOG_INF("Version: %s", DEBUGPROBE_VERSION);

    /* Get unique serial number */
    get_serial_string(serial, sizeof(serial));
    LOG_INF("Serial: %s", serial);

#ifdef CONFIG_USB_DEVICE_STACK_NEXT

#ifdef CONFIG_DEBUGPROBE_DAP
    /* Initialize GPIO pins */
    ret = gpio_init_pins();
    if (ret < 0) {
        LOG_ERR("GPIO init failed: %d", ret);
        return ret;
    }

    /* Initialize DAP */
    dap_init();
    LOG_INF("DAP initialized");
#endif

    /* Initialize USB device with new stack */
    usbd_ctx = debugprobe_usbd_init(usb_msg_cb);
    if (usbd_ctx == NULL) {
        LOG_ERR("Failed to initialize USB device");
        return -ENODEV;
    }

    /* Enable USB device */
    ret = usbd_enable(usbd_ctx);
    if (ret != 0) {
        LOG_ERR("Failed to enable USB: %d", ret);
        return ret;
    }
    LOG_INF("USB enabled");

    /* Wait for USB to be configured before printing welcome message */
    {
        const struct device *cdc_dev = DEVICE_DT_GET_ONE(zephyr_cdc_acm_uart);
        int timeout = 30; /* 3 seconds max */

        while (!usb_configured && timeout > 0) {
            k_sleep(K_MSEC(100));
            timeout--;
        }

        /* Wait a bit more for terminal to be ready, then print welcome */
        if (usb_configured) {
            uint32_t dtr = 0;
            timeout = 50; /* 5 seconds for DTR - give user time to connect */

            while (timeout > 0) {
                if (device_is_ready(cdc_dev)) {
                    uart_line_ctrl_get(cdc_dev, UART_LINE_CTRL_DTR, &dtr);
                    if (dtr) {
                        break;
                    }
                }
                k_sleep(K_MSEC(100));
                timeout--;
            }

            /* Print welcome message with console test */
            printk("\n");
            printk("    DEBUGPROBE CONSOLE TEST\n");
            printk("Version: %s (Zephyr)\n", DEBUGPROBE_VERSION);
            printk("Serial: %s\n", serial);
            printk("\n");
            printk("If you see this message, the console is working!\n");
            printk("Waiting 3 seconds before continuing, Flash LEDs...\n");

            /* Flash LEDs to show we're in console test mode */
            for (int i = 0; i < 6; i++) {
                led_dap_running(i % 2 == 0);
                k_sleep(K_MSEC(500));
            }

            printk("Console test complete. Starting DAP...\n\n");
        }
    }

    /*
     * Create threads
     *
     * Note: USB handling is event-driven via Zephyr callbacks (no thread needed).
     * DAP thread is created by usbd_dap.c when the USB class is initialized.
     * Only UART thread is created here for CDC-UART bridge.
     */

#ifdef CONFIG_DEBUGPROBE_CDC_UART
    /* UART thread starts suspended - resumed when USB is configured */
    uart_tid = k_thread_create(&uart_thread_data, uart_thread_stack,
                               K_THREAD_STACK_SIZEOF(uart_thread_stack),
                               uart_thread_entry, NULL, NULL, NULL,
                               UART_THREAD_PRIORITY, 0, K_NO_WAIT);
    k_thread_name_set(uart_tid, "uart_thread");
    k_thread_suspend(uart_tid);
    LOG_INF("UART thread created");
#endif

    /* Resume threads if USB was already configured during init */
    if (usb_configured) {
        LOG_INF("USB already configured, resuming threads");
        resume_threads();
    }
#else
    LOG_INF("Running in simulation mode (no USB)");
#endif /* CONFIG_USB_DEVICE_STACK_NEXT */

    /* Main loop - can be used for monitoring or additional tasks */
    while (1) {
        k_sleep(K_SECONDS(1));
        /* Could add watchdog feed here */
    }

    return 0;
}

#ifdef CONFIG_USB_DEVICE_STACK_NEXT
/*
 * USB Configured Check
 */
bool is_usb_configured(void)
{
    return usb_configured;
}
#endif /* CONFIG_USB_DEVICE_STACK_NEXT */
```

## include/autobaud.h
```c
/* SPDX-License-Identifier: MIT
 * Copyright (c) 2021-2023 Raspberry Pi (Trading) Ltd.
 * Copyright (c) 2026 Vincent Jardin <vjardin@free.fr>
 *
 * Debugprobe Zephyr Port - Autobaud Detection Header
 *
 * Automatic baud rate detection using PIO edge timing measurement.
 */

#pragma once

#include <zephyr/kernel.h>
#include <stdint.h>
#include <stdbool.h>

#ifdef CONFIG_SOC_RP2040

/*
 * Autobaud PIO Program - Pre-assembled instructions
 *
 * Original assembly (autobaud.pio):
 *
 * .program autobaud
 *
 * .wrap_target
 * falling_edge:
 *     wait 0 pin 0                    ; falling edge detected
 *     set x, 0                        ; set cycle counter to 0
 *     mov x, ~x                       ; x = 0xFFFFFFFF
 *
 * count_cycles:
 *     jmp pin rising_edge             ; if line went high, exit loop
 *     jmp x-- count_cycles            ; otherwise, decrement and continue
 *
 * rising_edge:
 *     mov isr, x                      ; save elapsed cycle count
 *     push noblock                    ; push to FIFO
 *     jmp falling_edge                ; repeat
 * .wrap
 */

/* Pre-assembled PIO instructions for autobaud */
static const uint16_t pio_autobaud_instructions[] = {
    /* 0: wait 0 pin 0                 - falling_edge (wrap_target) */
    0x2020,
    /* 1: set x, 0                     */
    0xe020,
    /* 2: mov x, ~x                    - x = 0xFFFFFFFF */
    0xa02f,
    /* 3: jmp pin 5                    - count_cycles: jmp to rising_edge */
    0x00c5,
    /* 4: jmp x-- 3                    - continue counting */
    0x0043,
    /* 5: mov isr, x                   - rising_edge */
    0xa0c1,
    /* 6: push noblock                 */
    0x8000,
    /* 7: jmp 0                        - back to falling_edge */
    0x0000,
};

#define PIO_AUTOBAUD_PROGRAM_LENGTH  ARRAY_SIZE(pio_autobaud_instructions)
#define PIO_AUTOBAUD_WRAP_TARGET     0
#define PIO_AUTOBAUD_WRAP            7

/* Baud rate detection result */
struct autobaud_result {
    uint32_t baud;      /* Detected baud rate */
    float validity;     /* Confidence score (0.0-1.0) */
};

/**
 * @brief Start autobaud detection
 *
 * Starts the PIO state machine to measure edge timing on the UART RX pin.
 * The detection runs in the background.
 *
 * @param rx_pin GPIO pin number for UART RX
 * @return 0 on success, negative error code otherwise
 */
int autobaud_start(uint8_t rx_pin);

/**
 * @brief Stop autobaud detection
 */
void autobaud_stop(void);

/**
 * @brief Check if autobaud is running
 *
 * @return true if detection is active
 */
bool autobaud_is_running(void);

/**
 * @brief Get detected baud rate
 *
 * Non-blocking call to check if a baud rate has been detected.
 *
 * @param result Pointer to store detection result
 * @return true if a valid baud rate was detected
 */
bool autobaud_get_result(struct autobaud_result *result);

/**
 * @brief Wait for baud rate detection
 *
 * Blocking call that waits until a valid baud rate is detected
 * or timeout expires.
 *
 * @param result Pointer to store detection result
 * @param timeout_ms Maximum time to wait in milliseconds
 * @return 0 on success, -ETIMEDOUT on timeout
 */
int autobaud_wait(struct autobaud_result *result, uint32_t timeout_ms);

#endif /* CONFIG_SOC_RP2040 */
```

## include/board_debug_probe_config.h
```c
/* SPDX-License-Identifier: MIT
 * Copyright (c) 2026 Vincent Jardin <vjardin@free.fr>
 *
 * Debugprobe Zephyr Port - Debug Probe Hardware Configuration
 *
 * Pin configuration for the Raspberry Pi Debug Probe hardware.
 */

#pragma once

/*
 * Debug Probe Hardware Pin Assignments
 * Reference: https://www.raspberrypi.com/documentation/microcontrollers/debug-probe.html
 */

/* SWD Interface Pins */
#define PROBE_PIN_SWCLK         11
#define PROBE_PIN_SWDIO         12
#define PROBE_PIN_SWDIR         13      /* Direction control for level shifter */
#define PROBE_PIN_RESET         14      /* Target nRESET */

/* JTAG Interface Pins (TCK/TMS shared with SWD) */
/* Note: Debug Probe hardware doesn't expose TDI/TDO, set to -1 */
#define PROBE_PIN_TCK           PROBE_PIN_SWCLK  /* TCK = SWCLK */
#define PROBE_PIN_TMS           PROBE_PIN_SWDIO  /* TMS = SWDIO */
#define PROBE_PIN_TDI           (-1)    /* TDI not available on Debug Probe */
#define PROBE_PIN_TDO           (-1)    /* TDO not available on Debug Probe */
#define PROBE_PIN_TRST          (-1)    /* nTRST not available */

/* UART Bridge Pins (directly active UART1 on J2 connector) */
#define PROBE_PIN_UART_TX       4       /* Target UART TX */
#define PROBE_PIN_UART_RX       5       /* Target UART RX */

/*
 * LED Pins - matching original debugprobe firmware
 *   D1 (Red, GPIO2):     USB connected indicator
 *   D2 (Green, GPIO7):   UART RX activity
 *   D3 (Yellow, GPIO8):  UART TX activity
 *   D4 (Green, GPIO15):  DAP connected
 *   D5 (Yellow, GPIO16): DAP running/activity
 */
#define PROBE_PIN_LED_USB       2       /* D1 Red - USB connected */
#define PROBE_PIN_LED_UART_RX   7       /* D2 Green - UART RX activity */
#define PROBE_PIN_LED_UART_TX   8       /* D3 Yellow - UART TX activity */
#define PROBE_PIN_LED_DAP_CONN  15      /* D4 Green - DAP connected */
#define PROBE_PIN_LED_DAP_RUN   16      /* D5 Yellow - DAP running */

/* Legacy aliases */
#define PROBE_PIN_LED_DAP       PROBE_PIN_LED_DAP_RUN
#define PROBE_PIN_LED_CONNECTED PROBE_PIN_LED_DAP_CONN
#define PROBE_PIN_LED_RUNNING   PROBE_PIN_LED_DAP_RUN

/* Level Shifter Control */
#define PROBE_PIN_IO_OEN        10      /* Output enable for level shifters */

/* UART Interface */
#define PROBE_UART_INTERFACE    uart1

/* Default Clock Speed */
#define PROBE_DEFAULT_CLOCK_HZ  1000000 /* 1 MHz default SWD clock */

/* Maximum Clock Speed */
#define PROBE_MAX_CLOCK_HZ      24000000 /* 24 MHz max with PIO */
```

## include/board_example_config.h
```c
/* SPDX-License-Identifier: MIT
 * Copyright (c) 2026 Vincent Jardin <vjardin@free.fr>
 *
 * Debugprobe Zephyr Port - Example Board Configuration
 *
 * Template for creating custom board configurations.
 * Copy this file and modify pin assignments for your hardware.
 */

#pragma once

/*
 * Custom Board Pin Assignments
 *
 * Modify these definitions to match your hardware setup.
 * All pins use GPIO numbers.
 */

/* SWD Interface Pins (REQUIRED) */
#define PROBE_PIN_SWCLK         2       /* SWD clock output */
#define PROBE_PIN_SWDIO         3       /* SWD data I/O */

/* Optional SWD pins - set to (-1) if not available */
#define PROBE_PIN_SWDIR         (-1)    /* Direction control for level shifter */
#define PROBE_PIN_RESET         (-1)    /* Target nRESET */

/* JTAG Interface Pins (OPTIONAL - TCK/TMS shared with SWD) */
#define PROBE_PIN_TCK           PROBE_PIN_SWCLK  /* TCK = SWCLK */
#define PROBE_PIN_TMS           PROBE_PIN_SWDIO  /* TMS = SWDIO */
#define PROBE_PIN_TDI           (-1)    /* TDI output to target */
#define PROBE_PIN_TDO           (-1)    /* TDO input from target */
#define PROBE_PIN_TRST          (-1)    /* nTRST (active low reset) */

/* UART Bridge Pins (OPTIONAL - set to -1 to disable) */
#define PROBE_PIN_UART_TX       4       /* UART TX to target */
#define PROBE_PIN_UART_RX       5       /* UART RX from target */

/* LED Pins (OPTIONAL - set to -1 if not available) */
#define PROBE_PIN_LED_DAP       (-1)    /* DAP activity LED */
#define PROBE_PIN_LED_UART_TX   (-1)    /* UART TX activity */
#define PROBE_PIN_LED_UART_RX   (-1)    /* UART RX activity */
#define PROBE_PIN_LED_CONNECTED (-1)    /* Target connected indicator */
#define PROBE_PIN_LED_RUNNING   (-1)    /* Target running indicator */

/* Level Shifter Control (OPTIONAL - set to -1 if not used) */
#define PROBE_PIN_IO_OEN        (-1)    /* Output enable for level shifters */

/* UART Interface Selection */
#define PROBE_UART_INTERFACE    uart0   /* uart0 or uart1 */

/* Clock Configuration */
#define PROBE_DEFAULT_CLOCK_HZ  1000000 /* 1 MHz default SWD clock */
#define PROBE_MAX_CLOCK_HZ      10000000 /* Maximum SWD clock speed */

/*
 * Notes:
 *
 * 1. SWCLK and SWDIO are the minimum required pins for SWD debugging.
 *
 * 2. If using a level shifter, configure PROBE_PIN_SWDIR to control
 *    the direction (high = output, low = input for SWDIO).
 *
 * 3. Target reset (nRESET) is optional but recommended for reliable
 *    target connection.
 *
 * 4. UART pins enable the CDC-UART bridge feature for serial console
 *    access to the target.
 *
 * 5. LEDs provide visual feedback but are not required for operation.
 *
 * 6. The level shifter output enable (IO_OEN) can be used to
 *    completely disable the debug interface when not in use.
 *
 * 7. JTAG requires TDI and TDO pins in addition to TCK/TMS (which are
 *    shared with SWCLK/SWDIO). If TDI/TDO are not available (-1),
 *    JTAG mode will have limited functionality (no data transfer).
 *
 * 8. nTRST is an optional JTAG reset signal (active low). Most targets
 *    don't require it as the TAP can be reset via TMS sequence.
 */
```
